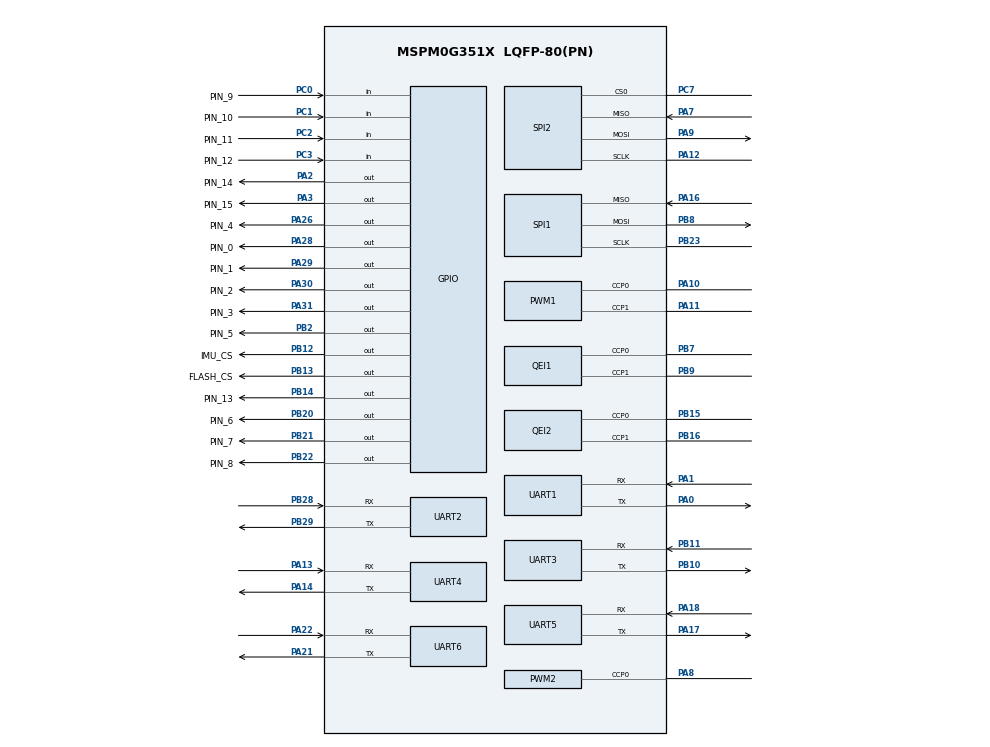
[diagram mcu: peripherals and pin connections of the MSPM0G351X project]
/**
 *
 * @cliArgs --device "MSPM0G351X" --part "Default" --package "LQFP-80(PN)" --product "mspm0_sdk@2.10.00.04"
 * @versions {"tool":"1.28.0+4712"}
 */

/**
 * Import the modules used in this configuration.
 */
const ADC12   = scripting.addModule("/ti/driverlib/ADC12", {}, false);
const ADC121  = ADC12.addInstance();
const GPIO    = scripting.addModule("/ti/driverlib/GPIO", {}, false);
const GPIO1   = GPIO.addInstance();
const GPIO2   = GPIO.addInstance();
const GPIO3   = GPIO.addInstance();
const GPIO4   = GPIO.addInstance();
const GPIO5   = GPIO.addInstance();
const GPIO6   = GPIO.addInstance();
const GPIO7   = GPIO.addInstance();
const GPIO8   = GPIO.addInstance();
const GPIO9   = GPIO.addInstance();
const PWM     = scripting.addModule("/ti/driverlib/PWM", {}, false);
const PWM1    = PWM.addInstance();
const PWM2    = PWM.addInstance();
const QEI     = scripting.addModule("/ti/driverlib/QEI", {}, false);
const QEI1    = QEI.addInstance();
const QEI2    = QEI.addInstance();
const SPI     = scripting.addModule("/ti/driverlib/SPI", {}, false);
const SPI1    = SPI.addInstance();
const SPI2    = SPI.addInstance();
const SYSCTL  = scripting.addModule("/ti/driverlib/SYSCTL");
const SYSTICK = scripting.addModule("/ti/driverlib/SYSTICK");
const TIMER   = scripting.addModule("/ti/driverlib/TIMER", {}, false);
const TIMER1  = TIMER.addInstance();
const TIMER2  = TIMER.addInstance();
const TIMER3  = TIMER.addInstance();
const UART    = scripting.addModule("/ti/driverlib/UART", {}, false);
const UART1   = UART.addInstance();
const UART2   = UART.addInstance();
const UART3   = UART.addInstance();
const UART4   = UART.addInstance();
const UART5   = UART.addInstance();
const UART6   = UART.addInstance();

/**
 * Write custom configuration values to the imported modules.
 */
const divider6       = system.clockTree["PLL_CLK2X_DIV"];
divider6.divideValue = 4;

const divider9       = system.clockTree["UDIV"];
divider9.divideValue = 2;

const multiplier2         = system.clockTree["PLL_QDIV"];
multiplier2.multiplyValue = 5;

const mux8       = system.clockTree["HSCLKMUX"];
mux8.inputSelect = "HSCLKMUX_SYSPLL2X";

ADC121.$name                             = "ADCGraySensor";
ADC121.peripheral.$assign                = "ADC1";
ADC121.peripheral.adcPin0.$assign        = "PA15";
ADC121.adcPin0Config.hideOutputInversion = scripting.forceWrite(false);
ADC121.adcPin0Config.$name               = "ti_driverlib_gpio_GPIOPinGeneric22";

const Board = scripting.addModule("/ti/driverlib/Board", {}, false);

GPIO1.$name                         = "Motor";
GPIO1.associatedPins.create(4);
GPIO1.associatedPins[0].$name       = "PIN_0";
GPIO1.associatedPins[0].pin.$assign = "PA28";
GPIO1.associatedPins[1].$name       = "PIN_1";
GPIO1.associatedPins[1].pin.$assign = "PA29";
GPIO1.associatedPins[2].$name       = "PIN_14";
GPIO1.associatedPins[2].pin.$assign = "PA2";
GPIO1.associatedPins[3].$name       = "PIN_15";
GPIO1.associatedPins[3].pin.$assign = "PA3";

GPIO2.$name                         = "CS";
GPIO2.associatedPins[0].$name       = "PIN_2";
GPIO2.associatedPins[0].pin.$assign = "PA30";

GPIO3.$name                         = "RES";
GPIO3.associatedPins[0].$name       = "PIN_3";
GPIO3.associatedPins[0].pin.$assign = "PA31";

GPIO4.$name                         = "DC";
GPIO4.associatedPins[0].$name       = "PIN_4";
GPIO4.associatedPins[0].pin.$assign = "PA26";

GPIO5.$name                         = "BL";
GPIO5.associatedPins[0].$name       = "PIN_5";
GPIO5.associatedPins[0].pin.$assign = "PB2";

GPIO6.$name                         = "GraySensor";
GPIO6.associatedPins.create(3);
GPIO6.associatedPins[0].$name       = "PIN_6";
GPIO6.associatedPins[0].pin.$assign = "PB20";
GPIO6.associatedPins[1].$name       = "PIN_7";
GPIO6.associatedPins[1].pin.$assign = "PB21";
GPIO6.associatedPins[2].$name       = "PIN_8";
GPIO6.associatedPins[2].pin.$assign = "PB22";

GPIO7.$name                              = "Key";
GPIO7.associatedPins.create(4);
GPIO7.associatedPins[0].$name            = "PIN_9";
GPIO7.associatedPins[0].direction        = "INPUT";
GPIO7.associatedPins[0].internalResistor = "PULL_UP";
GPIO7.associatedPins[0].pin.$assign      = "PC0";
GPIO7.associatedPins[1].$name            = "PIN_10";
GPIO7.associatedPins[1].direction        = "INPUT";
GPIO7.associatedPins[1].internalResistor = "PULL_UP";
GPIO7.associatedPins[1].pin.$assign      = "PC1";
GPIO7.associatedPins[2].$name            = "PIN_11";
GPIO7.associatedPins[2].direction        = "INPUT";
GPIO7.associatedPins[2].internalResistor = "PULL_UP";
GPIO7.associatedPins[2].pin.$assign      = "PC2";
GPIO7.associatedPins[3].$name            = "PIN_12";
GPIO7.associatedPins[3].direction        = "INPUT";
GPIO7.associatedPins[3].internalResistor = "PULL_UP";
GPIO7.associatedPins[3].pin.$assign      = "PC3";

GPIO8.$name                         = "LED";
GPIO8.associatedPins[0].$name       = "PIN_13";
GPIO8.associatedPins[0].pin.$assign = "PB14";

GPIO9.$name                          = "EncoderSharedBusCS";
GPIO9.associatedPins.create(2);
GPIO9.associatedPins[0].$name        = "IMU_CS";
GPIO9.associatedPins[0].initialValue = "SET";
GPIO9.associatedPins[0].pin.$assign  = "PB12";
GPIO9.associatedPins[1].$name        = "FLASH_CS";
GPIO9.associatedPins[1].initialValue = "SET";
GPIO9.associatedPins[1].pin.$assign  = "PB13";

PWM1.$name                      = "PWM_0";
PWM1.clockDivider               = 8;
PWM1.pwmMode                    = "EDGE_ALIGN_UP";
PWM1.peripheral.ccp0Pin.$assign = "PA10";
PWM1.peripheral.ccp1Pin.$assign = "PA11";
PWM1.PWM_CHANNEL_0.$name        = "ti_driverlib_pwm_PWMTimerCC0";
PWM1.PWM_CHANNEL_1.$name        = "ti_driverlib_pwm_PWMTimerCC1";
PWM1.ccp0PinConfig.$name        = "ti_driverlib_gpio_GPIOPinGeneric16";
PWM1.ccp1PinConfig.$name        = "ti_driverlib_gpio_GPIOPinGeneric17";

PWM2.$name                      = "PWM_1";
PWM2.ccIndex                    = [0];
PWM2.clockDivider               = 8;
PWM2.pwmMode                    = "EDGE_ALIGN_UP";
PWM2.PWM_CHANNEL_0.$name        = "ti_driverlib_pwm_PWMTimerCC2";
PWM2.PWM_CHANNEL_0.dutyCycle    = 50;
PWM2.ccp0PinConfig.$name        = "ti_driverlib_gpio_GPIOPinGeneric18";
PWM2.peripheral.$assign         = "TIMA0";
PWM2.peripheral.ccp0Pin.$assign = "PA8";

QEI1.$name                              = "Encoder1";
QEI1.peripheral.ccp0Pin.$assign         = "PB7";
QEI1.peripheral.ccp1Pin.$assign         = "PB9";
QEI1.ccp0PinConfig.hideOutputInversion  = scripting.forceWrite(false);
QEI1.ccp0PinConfig.onlyInternalResistor = scripting.forceWrite(false);
QEI1.ccp0PinConfig.passedPeripheralType = scripting.forceWrite("Digital");
QEI1.ccp0PinConfig.$name                = "ti_driverlib_gpio_GPIOPinGeneric12";
QEI1.ccp1PinConfig.hideOutputInversion  = scripting.forceWrite(false);
QEI1.ccp1PinConfig.onlyInternalResistor = scripting.forceWrite(false);
QEI1.ccp1PinConfig.passedPeripheralType = scripting.forceWrite("Digital");
QEI1.ccp1PinConfig.$name                = "ti_driverlib_gpio_GPIOPinGeneric13";

QEI2.$name                              = "Encoder2";
QEI2.peripheral.ccp0Pin.$assign         = "PB15";
QEI2.peripheral.ccp1Pin.$assign         = "PB16";
QEI2.ccp0PinConfig.hideOutputInversion  = scripting.forceWrite(false);
QEI2.ccp0PinConfig.onlyInternalResistor = scripting.forceWrite(false);
QEI2.ccp0PinConfig.passedPeripheralType = scripting.forceWrite("Digital");
QEI2.ccp0PinConfig.$name                = "ti_driverlib_gpio_GPIOPinGeneric14";
QEI2.ccp1PinConfig.hideOutputInversion  = scripting.forceWrite(false);
QEI2.ccp1PinConfig.onlyInternalResistor = scripting.forceWrite(false);
QEI2.ccp1PinConfig.passedPeripheralType = scripting.forceWrite("Digital");
QEI2.ccp1PinConfig.$name                = "ti_driverlib_gpio_GPIOPinGeneric15";

SPI1.$name                      = "SPI_0";
SPI1.frameFormat                = "MOTO3";
SPI1.sclkPinConfig.$name        = "ti_driverlib_gpio_GPIOPinGeneric19";
SPI1.mosiPinConfig.$name        = "ti_driverlib_gpio_GPIOPinGeneric20";
SPI1.misoPinConfig.$name        = "ti_driverlib_gpio_GPIOPinGeneric21";
SPI1.peripheral.$assign         = "SPI1";
SPI1.peripheral.sclkPin.$assign = "PB23";
SPI1.peripheral.mosiPin.$assign = "PB8";
SPI1.peripheral.misoPin.$assign = "PA16";

SPI2.$name                      = "SPI_1";
SPI2.peripheral.$assign         = "SPI0";
SPI2.peripheral.sclkPin.$assign = "PA12";
SPI2.peripheral.mosiPin.$assign = "PA9";
SPI2.peripheral.misoPin.$assign = "PA7";
SPI2.peripheral.cs0Pin.$assign  = "PC7";
SPI2.sclkPinConfig.$name        = "ti_driverlib_gpio_GPIOPinGeneric23";
SPI2.mosiPinConfig.$name        = "ti_driverlib_gpio_GPIOPinGeneric24";
SPI2.misoPinConfig.$name        = "ti_driverlib_gpio_GPIOPinGeneric25";
SPI2.cs0PinConfig.$name         = "ti_driverlib_gpio_GPIOPinGeneric26";

SYSCTL.forceDefaultClkConfig = true;
SYSCTL.clockTreeEn           = true;

SYSTICK.periodEnable      = true;
SYSTICK.interruptEnable   = true;
SYSTICK.systickEnable     = true;
SYSTICK.interruptPriority = "0";
SYSTICK.period            = 80000;

TIMER1.$name            = "TIMER_0";
TIMER1.timerMode        = "PERIODIC_UP";
TIMER1.timerPeriod      = "10 ms";
TIMER1.timerClkDiv      = 8;
TIMER1.interrupts       = ["ZERO"];
TIMER1.timerClkPrescale = 10;

TIMER2.$name            = "TIMER_1";
TIMER2.timerPeriod      = "20 ms";
TIMER2.timerClkDiv      = 8;
TIMER2.timerClkPrescale = 10;
TIMER2.timerMode        = "PERIODIC";

TIMER3.$name            = "TIMER_2";
TIMER3.timerClkDiv      = 8;
TIMER3.timerPeriod      = "50 ms";
TIMER3.timerClkPrescale = 10;
TIMER3.timerMode        = "PERIODIC";

UART1.$name                    = "UART_0";
UART1.targetBaudRate           = 115200;
UART1.peripheral.$assign       = "UART0";
UART1.peripheral.rxPin.$assign = "PA1";
UART1.peripheral.txPin.$assign = "PA0";
UART1.txPinConfig.$name        = "ti_driverlib_gpio_GPIOPinGeneric0";
UART1.rxPinConfig.$name        = "ti_driverlib_gpio_GPIOPinGeneric1";

UART2.$name                            = "UART_2";
UART2.targetBaudRate                   = 115200;
UART2.peripheral.$assign               = "UART5";
UART2.peripheral.rxPin.$assign         = "PB28";
UART2.peripheral.txPin.$assign         = "PB29";
UART2.txPinConfig.direction            = scripting.forceWrite("OUTPUT");
UART2.txPinConfig.hideOutputInversion  = scripting.forceWrite(false);
UART2.txPinConfig.onlyInternalResistor = scripting.forceWrite(false);
UART2.txPinConfig.passedPeripheralType = scripting.forceWrite("Digital");
UART2.txPinConfig.$name                = "ti_driverlib_gpio_GPIOPinGeneric4";
UART2.rxPinConfig.hideOutputInversion  = scripting.forceWrite(false);
UART2.rxPinConfig.onlyInternalResistor = scripting.forceWrite(false);
UART2.rxPinConfig.passedPeripheralType = scripting.forceWrite("Digital");
UART2.rxPinConfig.$name                = "ti_driverlib_gpio_GPIOPinGeneric5";

UART3.$name                            = "UART_3";
UART3.targetBaudRate                   = 115200;
UART3.peripheral.$assign               = "UART4";
UART3.peripheral.rxPin.$assign         = "PB11";
UART3.peripheral.txPin.$assign         = "PB10";
UART3.txPinConfig.direction            = scripting.forceWrite("OUTPUT");
UART3.txPinConfig.hideOutputInversion  = scripting.forceWrite(false);
UART3.txPinConfig.onlyInternalResistor = scripting.forceWrite(false);
UART3.txPinConfig.passedPeripheralType = scripting.forceWrite("Digital");
UART3.txPinConfig.$name                = "ti_driverlib_gpio_GPIOPinGeneric6";
UART3.rxPinConfig.hideOutputInversion  = scripting.forceWrite(false);
UART3.rxPinConfig.onlyInternalResistor = scripting.forceWrite(false);
UART3.rxPinConfig.passedPeripheralType = scripting.forceWrite("Digital");
UART3.rxPinConfig.$name                = "ti_driverlib_gpio_GPIOPinGeneric7";

UART4.$name                            = "UART_4";
UART4.targetBaudRate                   = 115200;
UART4.peripheral.$assign               = "UART3";
UART4.peripheral.rxPin.$assign         = "PA13";
UART4.peripheral.txPin.$assign         = "PA14";
UART4.txPinConfig.direction            = scripting.forceWrite("OUTPUT");
UART4.txPinConfig.hideOutputInversion  = scripting.forceWrite(false);
UART4.txPinConfig.onlyInternalResistor = scripting.forceWrite(false);
UART4.txPinConfig.passedPeripheralType = scripting.forceWrite("Digital");
UART4.txPinConfig.$name                = "ti_driverlib_gpio_GPIOPinGeneric8";
UART4.rxPinConfig.hideOutputInversion  = scripting.forceWrite(false);
UART4.rxPinConfig.onlyInternalResistor = scripting.forceWrite(false);
UART4.rxPinConfig.passedPeripheralType = scripting.forceWrite("Digital");
UART4.rxPinConfig.$name                = "ti_driverlib_gpio_GPIOPinGeneric9";

UART5.$name                            = "UART_5";
UART5.targetBaudRate                   = 115200;
UART5.peripheral.rxPin.$assign         = "PA18";
UART5.peripheral.txPin.$assign         = "PA17";
UART5.txPinConfig.direction            = scripting.forceWrite("OUTPUT");
UART5.txPinConfig.hideOutputInversion  = scripting.forceWrite(false);
UART5.txPinConfig.onlyInternalResistor = scripting.forceWrite(false);
UART5.txPinConfig.passedPeripheralType = scripting.forceWrite("Digital");
UART5.txPinConfig.$name                = "ti_driverlib_gpio_GPIOPinGeneric10";
UART5.rxPinConfig.hideOutputInversion  = scripting.forceWrite(false);
UART5.rxPinConfig.onlyInternalResistor = scripting.forceWrite(false);
UART5.rxPinConfig.passedPeripheralType = scripting.forceWrite("Digital");
UART5.rxPinConfig.$name                = "ti_driverlib_gpio_GPIOPinGeneric11";

UART6.$name                            = "UART_1";
UART6.targetBaudRate                   = 115200;
UART6.peripheral.$assign               = "UART7";
UART6.peripheral.rxPin.$assign         = "PA22";
UART6.peripheral.txPin.$assign         = "PA21";
UART6.txPinConfig.direction            = scripting.forceWrite("OUTPUT");
UART6.txPinConfig.hideOutputInversion  = scripting.forceWrite(false);
UART6.txPinConfig.onlyInternalResistor = scripting.forceWrite(false);
UART6.txPinConfig.passedPeripheralType = scripting.forceWrite("Digital");
UART6.txPinConfig.$name                = "ti_driverlib_gpio_GPIOPinGeneric2";
UART6.rxPinConfig.hideOutputInversion  = scripting.forceWrite(false);
UART6.rxPinConfig.onlyInternalResistor = scripting.forceWrite(false);
UART6.rxPinConfig.passedPeripheralType = scripting.forceWrite("Digital");
UART6.rxPinConfig.$name                = "ti_driverlib_gpio_GPIOPinGeneric3";

/**
 * Pinmux solution for unlocked pins/peripherals. This ensures that minor changes to the automatic solver in a future
 * version of the tool will not impact the pinmux you originally saw.  These lines can be completely deleted in order to
 * re-solve from scratch.
 */
Board.peripheral.$suggestSolution          = "DEBUGSS";
Board.peripheral.swclkPin.$suggestSolution = "PA20";
Board.peripheral.swdioPin.$suggestSolution = "PA19";
PWM1.peripheral.$suggestSolution           = "TIMG12";
QEI1.peripheral.$suggestSolution           = "TIMG9";
QEI2.peripheral.$suggestSolution           = "TIMG8";
TIMER1.peripheral.$suggestSolution         = "TIMG6";
TIMER2.peripheral.$suggestSolution         = "TIMG0";
TIMER3.peripheral.$suggestSolution         = "TIMA1";
UART5.peripheral.$suggestSolution          = "UART1";
